VERSION ""

NS_ :

BS_:

BU_:
VAL_TABLE_ MPPT_Enabled 0 "Disabled" 1 "Enabled" ;
VAL_TABLE_ MPPT_Mode 0 "constant Input Voltage" 1 "constant Input Current" 2 "Minimum Input Current" 3 "constant Output Voltage" 4 "Constant Output Current" 5 "Temperature De-rating" 6 "Fault" ;
VAL_TABLE_ MPPT_Fault 0 "OK(No Fault)" 1 "Configuration Error" 2 "Input Over Voltage" 3 "Output Over Voltage" 4 "Output Over Current" 5 "Input Over Current" 6 "Input Under Current" 7 "Phase Over Current" 8 "Fault" ;

BO_ 2 BPS_Trip: 1 Vector__XXX
 SG_ BPS_Trip : 0|1@0+ (1,0) [0|1] "" Vector__XXX

BO_ 257 BPS_All_Clea: 1 Vector__XXX
 SG_ BPS_All_Clear : 0|1@0+ (1,0) [0|1] "" Vector__XXX

BO_ 258 BPS_Contactor_State: 1 Vector__XXX
 SG_ Array_Contactor : 0|1@0+ (1,0) [0|1] "" Vector__XXX
 SG_ HV_Contactor : 2|1@0+ (1,0) [0|1] "" Vector__XXX

BO_ 259 BPS_Current: 4 Vector__XXX
 SG_ Current : 0|32@1- (1,0) [-20000|100000] "mA" Vector__XXX

BO_ 260 BPS_Voltage_Array: 5 Vector__XXX
 SG_ Voltage_idx : 0|8@1+ (1,0) [0|31] "" Vector__XXX
 SG_ Voltage_Value : 8|32@1+ (1,0) [0|1000000] "mV" Vector__XXX

BO_ 261 BPS_Temperature_Array: 5 Vector__XXX
 SG_ Temperature_idx : 0|8@1+ (1,0) [0|31] "" Vector__XXX
 SG_ Temperature_Value : 8|32@1+ (1,0) [0|1000000] "mC" Vector__XXX

BO_ 262 BPS_SOC: 4 Vector__XXX
 SG_ SoC : 0|32@1+ (1,0) [0|100] "%" Vector__XXX

BO_ 263 BPS_WDog_Trigger: 1 Vector__XXX
 SG_ WDog_Trig : 0|1@0+ (1,0) [0|1] "" Vector__XXX

BO_ 264 BPS_CAN_Error: 1 Vector__XXX
 SG_ BPS_CAN_Error : 0|1@0+ (1,0) [0|1] "" Vector__XXX

BO_ 265 BPS_Command: 8 Vector__XXX
 SG_ BPS_Command : 0|32@1+ (1,0) [0|0] "" Vector__XXX

BO_ 267 BPS_Supplemental_Voltage: 2 Vector__XXX
 SG_ Supplemental_Voltage : 0|16@1+ (1,0) [0|65535] "mV" Vector__XXX

BO_ 268 BPS_Charge_Enabled: 1 Vector__XXX
 SG_ Charge_Enabled : 0|1@0+ (1,0) [0|1] "" Vector__XXX

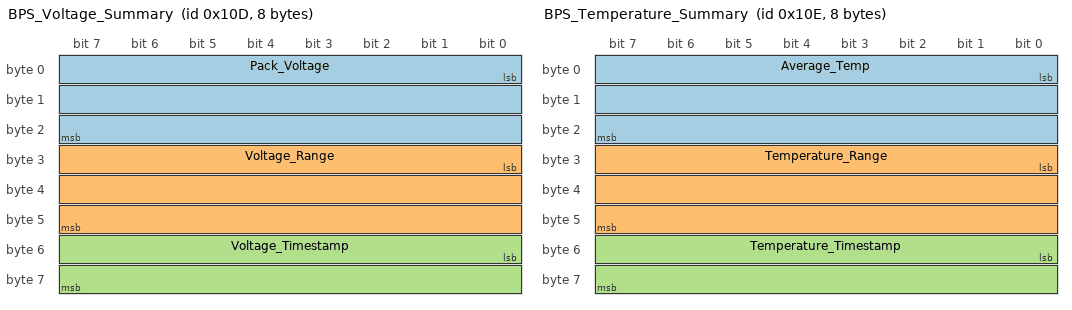
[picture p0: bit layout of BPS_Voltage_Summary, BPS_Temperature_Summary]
BO_ 269 BPS_Voltage_Summary: 8 Vector__XXX
 SG_ Pack_Voltage : 0|24@1+ (1,0) [0|16777215] "mV" Vector__XXX
 SG_ Voltage_Range : 24|24@1+ (1,0) [0|16777215] "mV" Vector__XXX
 SG_ Voltage_Timestamp : 48|16@1+ (1,0) [0|65535] "ms" Vector__XXX

BO_ 270 BPS_Temperature_Summary: 8 Vector__XXX
 SG_ Average_Temp : 0|24@1+ (1,0) [0|0] "mC" Vector__XXX
 SG_ Temperature_Range : 24|24@1+ (1,0) [0|0] "mC" Vector__XXX
 SG_ Temperature_Timestamp : 48|16@1+ (1,0) [0|0] "ms" Vector__XXX

BO_ 271 BPS_Fault_State: 1 Vector__XXX
 SG_ BPS_Fault_State : 0|8@1+ (1,0) [0|12] "" Vector__XXX

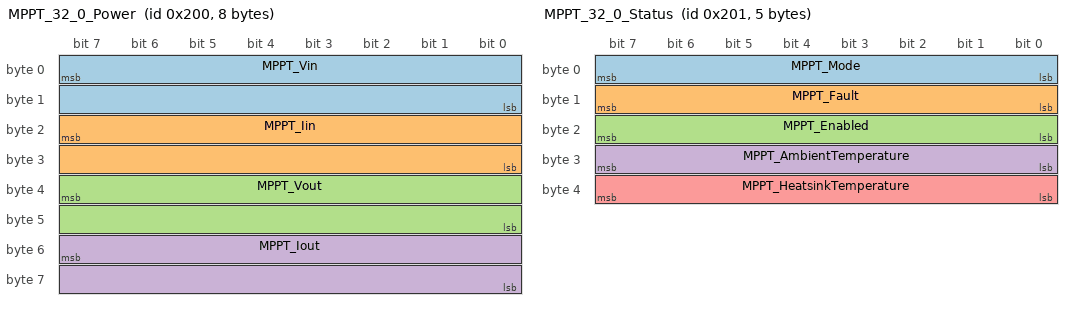
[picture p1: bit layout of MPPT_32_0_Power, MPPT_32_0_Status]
BO_ 512 MPPT_32_0_Power: 8 Vector__XXX
 SG_ MPPT_Vin : 7|16@0- (0.01,0) [-327.68|327.67] "V" Vector__XXX
 SG_ MPPT_Iin : 23|16@0- (0.0005,0) [-16.384|16.3835] "A" Vector__XXX
 SG_ MPPT_Vout : 39|16@0- (0.01,0) [-327.68|327.67] "V" Vector__XXX
 SG_ MPPT_Iout : 55|16@0- (0.0005,0) [0|0] "A" Vector__XXX

BO_ 513 MPPT_32_0_Status: 5 Vector__XXX
 SG_ MPPT_Mode : 0|8@1+ (1,0) [0|0] "" Vector__XXX
 SG_ MPPT_Fault : 8|8@1+ (1,0) [0|0] "" Vector__XXX
 SG_ MPPT_Enabled : 16|8@1- (1,0) [0|0] "" Vector__XXX
 SG_ MPPT_AmbientTemperature : 31|8@0- (1,0) [-128|127] "C" Vector__XXX
 SG_ MPPT_HeatsinkTemperature : 39|8@0- (1,0) [-128|127] "C" Vector__XXX

BO_ 521 MPPT_32_0_SetMode: 1 Vector__XXX
 SG_ Boost_Enable : 0|1@1+ (1,0) [0|1] "" Vector__XXX

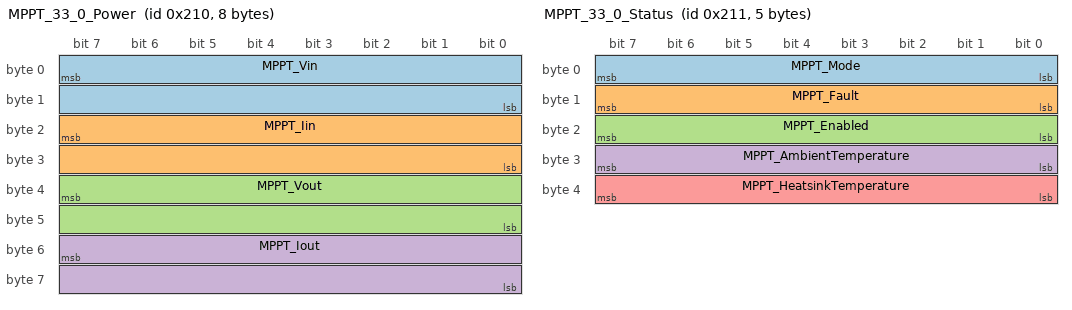
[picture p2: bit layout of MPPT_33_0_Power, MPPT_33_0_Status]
BO_ 528 MPPT_33_0_Power: 8 Vector__XXX
 SG_ MPPT_Vin : 7|16@0- (0.01,0) [-327.68|327.67] "V" Vector__XXX
 SG_ MPPT_Iin : 23|16@0- (0.0005,0) [-16.384|16.3835] "A" Vector__XXX
 SG_ MPPT_Vout : 39|16@0- (0.01,0) [-327.68|327.67] "V" Vector__XXX
 SG_ MPPT_Iout : 55|16@0- (0.0005,0) [0|0] "A" Vector__XXX

BO_ 529 MPPT_33_0_Status: 5 Vector__XXX
 SG_ MPPT_Mode : 0|8@1+ (1,0) [0|0] "" Vector__XXX
 SG_ MPPT_Fault : 8|8@1+ (1,0) [0|0] "" Vector__XXX
 SG_ MPPT_Enabled : 16|8@1- (1,0) [0|0] "" Vector__XXX
 SG_ MPPT_AmbientTemperature : 31|8@0- (1,0) [-128|127] "C" Vector__XXX
 SG_ MPPT_HeatsinkTemperature : 39|8@0- (1,0) [-128|127] "C" Vector__XXX

BO_ 537 MPPT_33_0_SetMode: 1 Vector__XXX
 SG_ Boost_Enable : 0|1@1+ (1,0) [0|1] "" Vector__XXX

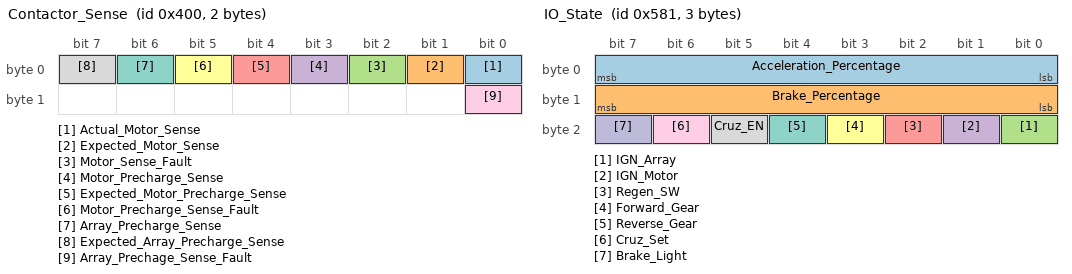
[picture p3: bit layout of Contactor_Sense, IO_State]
BO_ 1024 Contactor_Sense: 2 Vector__XXX
 SG_ Actual_Motor_Sense : 0|1@1+ (1,0) [0|1] "" Vector__XXX
 SG_ Expected_Motor_Sense : 1|1@1+ (1,0) [0|0] "" Vector__XXX
 SG_ Motor_Sense_Fault : 2|1@1+ (1,0) [0|1] "" Vector__XXX
 SG_ Motor_Precharge_Sense : 3|1@1+ (1,0) [0|1] "" Vector__XXX
 SG_ Expected_Motor_Precharge_Sense : 4|1@1+ (1,0) [0|1] "" Vector__XXX
 SG_ Motor_Precharge_Sense_Fault : 5|1@1+ (1,0) [0|1] "" Vector__XXX
 SG_ Array_Precharge_Sense : 6|1@1+ (1,0) [0|1] "" Vector__XXX
 SG_ Expected_Array_Precharge_Sense : 7|1@1+ (1,0) [0|1] "" Vector__XXX
 SG_ Array_Prechage_Sense_Fault : 8|1@1+ (1,0) [0|1] "" Vector__XXX

BO_ 1025 Precharge_Timeout: 1 Vector__XXX
 SG_ Motor_Precharge_Timeout : 0|1@1+ (1,0) [0|1] "" Vector__XXX
 SG_ Array_Precharge_Timeout : 1|1@1+ (1,0) [0|0] "" Vector__XXX

BO_ 1409 IO_State: 3 Vector__XXX
 SG_ Acceleration_Percentage : 0|8@1+ (1,0) [0|100] "Percentage" Vector__XXX
 SG_ Brake_Percentage : 8|8@1+ (1,0) [0|100] "Percentage the brake is pressed" Vector__XXX
 SG_ IGN_Array : 16|1@1+ (1,0) [0|1] "Array Ignition On" Vector__XXX
 SG_ IGN_Motor : 17|1@1+ (1,0) [0|1] "Motor Ignition On" Vector__XXX
 SG_ Regen_SW : 18|1@1+ (1,0) [0|1] "Regen Switched On" Vector__XXX
 SG_ Forward_Gear : 19|1@1+ (1,0) [0|1] "Forward switch" Vector__XXX
 SG_ Reverse_Gear : 20|1@1+ (1,0) [0|1] "Reverse switch" Vector__XXX
 SG_ Cruz_EN : 21|1@1+ (1,0) [0|1] "Cruise Enable" Vector__XXX
 SG_ Cruz_Set : 22|1@1+ (1,0) [0|1] "Cruise Set" Vector__XXX
 SG_ Brake_Light : 23|1@1+ (1,0) [0|1] "Brakelight state" Vector__XXX

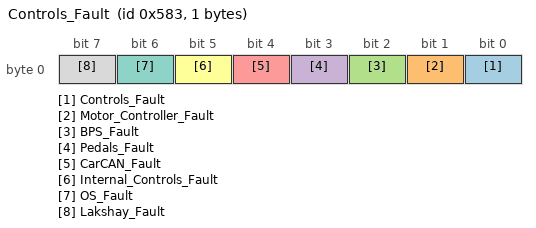
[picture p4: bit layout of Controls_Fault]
BO_ 1411 Controls_Fault: 1 Vector__XXX
 SG_ Controls_Fault : 0|1@1+ (1,0) [0|1] "" Vector__XXX
 SG_ Motor_Controller_Fault : 1|1@1+ (1,0) [0|1] "" Vector__XXX
 SG_ BPS_Fault : 2|1@1+ (1,0) [0|1] "" Vector__XXX
 SG_ Pedals_Fault : 3|1@1+ (1,0) [0|0] "" Vector__XXX
 SG_ CarCAN_Fault : 4|1@1+ (1,0) [0|1] "" Vector__XXX
 SG_ Internal_Controls_Fault : 5|1@1+ (1,0) [0|1] "" Vector__XXX
 SG_ OS_Fault : 6|1@1+ (1,0) [0|1] "" Vector__XXX
 SG_ Lakshay_Fault : 7|1@1+ (1,0) [0|1] "" Vector__XXX

BO_ 1412 Motor_Controller_Safe: 1 Vector__XXX
 SG_ Motor_Safe : 0|1@1+ (1,0) [0|1] "" Vector__XXX
 SG_ Motor_Controller_Error : 1|1@1+ (1,0) [0|1] "" Vector__XXX

BO_ 1413 Pedals_Raw_Voltage: 4 Vector__XXX
 SG_ Brake_Raw : 0|15@1- (1,0) [0|3300] "mV" Vector__XXX
 SG_ Accel_Raw : 16|15@1- (1,0) [0|3300] "mV" Vector__XXX

CM_ BO_ 1409 "IO State of Controls";
CM_ BO_ 1411 "Controls Fault State";
CM_ BO_ 1412 "Motor Safe State";
BA_DEF_ BO_  "VFrameFormat" ENUM  "StandardCAN","ExtendedCAN","reserved","J1939PG";
BA_DEF_  "DatabaseVersion" STRING ;
BA_DEF_  "BusType" STRING ;
BA_DEF_  "ProtocolType" STRING ;
BA_DEF_  "DatabaseCompiler" STRING ;
BA_DEF_DEF_  "VFrameFormat" "J1939PG";
BA_DEF_DEF_  "DatabaseVersion" "DEMO PLUS";
BA_DEF_DEF_  "BusType" "";
BA_DEF_DEF_  "ProtocolType" "";
BA_DEF_DEF_  "DatabaseCompiler" "";
BA_ "ProtocolType" "J1939";
BA_ "BusType" "CAN";
BA_ "DatabaseCompiler" "CSS ELECTRONICS (WWW.CSSELECTRONICS.COM)";
BA_ "DatabaseVersion" "1.0.0";
BA_ "VFrameFormat" BO_ 512 0;
BA_ "VFrameFormat" BO_ 513 0;
BA_ "VFrameFormat" BO_ 521 0;
BA_ "VFrameFormat" BO_ 528 0;
BA_ "VFrameFormat" BO_ 529 0;
BA_ "VFrameFormat" BO_ 537 0;
